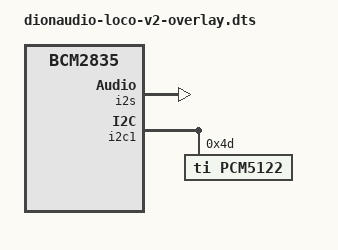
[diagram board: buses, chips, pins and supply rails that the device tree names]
/*
 * Definitions for Dion Audio LOCO-V2 DAC-AMP
 *  eg. dtoverlay=dionaudio-loco-v2
 *
 * PCM5242 DAC (in software mode) and TPA3255 AMP.
 */

/dts-v1/;
/plugin/;

/ {
	compatible = "brcm,bcm2835";

	fragment@0 {
		target = <&sound>;
		frag0: __overlay__ {
			compatible = "dionaudio,dionaudio-loco-v2";
			i2s-controller = <&i2s>;
			status = "okay";
		};
	};

	fragment@1 {
		target = <&i2s>;
		__overlay__ {
			status = "okay";
		};
	};

	fragment@2 {
		target = <&i2c1>;
		__overlay__ {
			#address-cells = <1>;
			#size-cells = <0>;
			status = "okay";

			pcm5122@4c {
				#sound-dai-cells = <0>;
				compatible = "ti,pcm5122";
				reg = <0x4d>;
				status = "okay";
			};
		};
	};

	__overrides__ {
		24db_digital_gain = <&frag0>,"dionaudio,24db_digital_gain?";
	};
};
